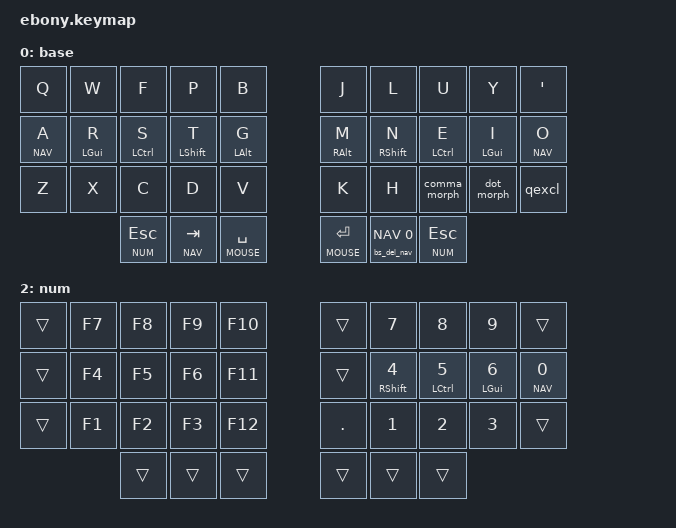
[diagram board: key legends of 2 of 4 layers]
#include <behaviors.dtsi>
#include <dt-bindings/zmk/keys.h>
#include <dt-bindings/zmk/bt.h>
#include <dt-bindings/zmk/outputs.h>
#include <dt-bindings/zmk/mouse.h>

#define DEF 0
#define NAV 1
#define NUM 2
#define MOUSE 3

#include "./key_positions.h"
#include "./helper.h"
#include "./combos.dtsi"


&mmv {
  acceleration-exponent = <1>;      // 1
  time-to-max-speed-ms = <1500>;    // 40
  delay-ms = <0>;                   // 0
};

&mwh {
  acceleration-exponent = <1>;      // 0
  time-to-max-speed-ms = <5000>;    // 40
  delay-ms = <0>;                   // 10
};

#define U_MOUSE_MOVE_MAX 1250       // 600
#define U_MOUSE_SCROLL_MAX 100      // 10

#undef MOVE_UP
#undef MOVE_DOWN
#undef MOVE_LEFT
#undef MOVE_RIGHT
#define MOVE_UP MOVE_VERT(-U_MOUSE_MOVE_MAX)
#define MOVE_DOWN MOVE_VERT(U_MOUSE_MOVE_MAX)
#define MOVE_LEFT MOVE_HOR(-U_MOUSE_MOVE_MAX)
#define MOVE_RIGHT MOVE_HOR(U_MOUSE_MOVE_MAX)

#undef SCROLL_UP
#undef SCROLL_DOWN
#undef SCROLL_LEFT
#undef SCROLL_RIGHT
#define SCROLL_UP SCROLL_VERT(U_MOUSE_SCROLL_MAX)
#define SCROLL_DOWN SCROLL_VERT(-U_MOUSE_SCROLL_MAX)
#define SCROLL_LEFT SCROLL_HOR(-U_MOUSE_SCROLL_MAX)
#define SCROLL_RIGHT SCROLL_HOR(U_MOUSE_SCROLL_MAX)

#define U_BTN1 &mkp MB1
#define U_BTN2 &mkp MB2
#define U_BTN3 &mkp MB3
#define U_MS_U &mmv MOVE_UP
#define U_MS_D &mmv MOVE_DOWN
#define U_MS_L &mmv MOVE_LEFT
#define U_MS_R &mmv MOVE_RIGHT
#define U_WH_U &mwh SCROLL_UP
#define U_WH_D &mwh SCROLL_DOWN
#define U_WH_L &mwh SCROLL_LEFT
#define U_WH_R &mwh SCROLL_RIGHT


#define XXX &none
#define ___ &trans

#define QUICK_TAP_MS 175

&sk {  // sticky-key config
    release-after-ms = <900>;  // release after 0.6s
    quick-release;             // no double capitalization when rolling keys
};

&sl {  // sticky-layer config
    ignore-modifiers;          // allow chording sticky mods & layers
};

&lt {  // layer-tap config
    flavor = "balanced";
    tapping-term-ms = <200>;
    quick-tap-ms = <QUICK_TAP_MS>;
};

/* Homerow mods */

#define KEYS_L LT0 LT1 LT2 LT3 LT4 LM0 LM1 LM2 LM3 LM4 LB0 LB1 LB2 LB3 LB4  // left hand
#define KEYS_R RT0 RT1 RT2 RT3 RT4 RM0 RM1 RM2 RM3 RM4 RB0 RB1 RB2 RB3 RB4  // right hand
#define THUMBS LH3 LH2 LH1 LH0 RH0 RH1 RH2 RH3

#define MAKE_HRM(NAME, HOLD, TAP, TRIGGER_POS) \
    ZMK_BEHAVIOR(NAME, hold_tap, \
        flavor = "balanced"; \
        tapping-term-ms = <280>; \
        quick-tap-ms = <QUICK_TAP_MS>; \
        #global-quick-tap-ms = <150>; \
        bindings = <HOLD>, <TAP>; \
        hold-trigger-key-positions = <TRIGGER_POS>; \
        hold-trigger-on-release; \
    )

MAKE_HRM(hml, &kp, &kp, KEYS_R THUMBS)  // left-hand HRMs
MAKE_HRM(hmr, &kp, &kp, KEYS_L THUMBS)  // right-hand HRMs

MAKE_HRM(hmll, &mo, &kp, KEYS_R THUMBS)  // left-hand HRMs
MAKE_HRM(hmlr, &mo, &kp, KEYS_L THUMBS)  // right-hand HRMs

MAKE_HRM(hml_repeat, &kp, &key_repeat, KEYS_R THUMBS)  // used for HRM-combo
MAKE_HRM(hmr_lpar_lt, &kp, &lpar_lt, KEYS_L THUMBS)    // "    "   "   "
MAKE_HRM(hmr_rpar_gt, &kp, &rpar_gt, KEYS_L THUMBS)    // "    "   "   "

/* Nav cluster */

// long-tap action on hold, short-tap action on all interrupts
#define MT_CORE \
    flavor = "tap-preferred"; \
    tapping-term-ms = <220>; \
    quick-tap-ms = <220>; \
    hold-trigger-key-positions = <0>;

&mt { MT_CORE };

#define NAV_BSPC  &mt LC(BSPC) BSPC    // tap: bspc  | long-tap: delete word backward
#define NAV_DEL   &mt LC(DEL)  DEL     // tap: del   | long-tap: delete word forward

/* Caps-word, num-word and smart-mouse */

// tap: sticky-shift | shift + tap/ double-tap: caps-word | hold: shift
ZMK_BEHAVIOR(smart_shft, mod_morph,
    bindings = <&kp RETURN>, <&caps_word>;
    mods = <(MOD_LSFT)>;
)
&caps_word {  // mods deactivate caps-word, requires PR #1451
    /delete-property/ ignore-modifiers;
};

// tap: num-word | double-tap: sticky num-layer | hold: num-layer
#define SMART_NUM &smart_num NUM 0
ZMK_BEHAVIOR(smart_num, hold_tap,
    flavor = "balanced";
    tapping-term-ms = <200>;
    quick-tap-ms = <QUICK_TAP_MS>;
    bindings = <&mo>, <&num_dance>;
)
ZMK_BEHAVIOR(num_dance, tap_dance,
    tapping-term-ms = <200>;
    bindings = <&num_word>, <&sl NUM>;  // reverse this for sticky-num on single tap
)
&num_word {  // num-word, requires PR #1451
    layers = <NUM>;
    continue-list = <BSPC DEL DOT COMMA PLUS MINUS STAR FSLH EQUAL>;
};

/* Custom behaviors */
// Sticky layer + sticky shift (workaround for issue #1421)
//ZMK_BEHAVIOR(sls, sticky_key,
//    release-after-ms = <1000>;
//    bindings = <&uc_shift>;
//    ignore-modifiers;
//)
//ZMK_BEHAVIOR(uc_shift, macro,
//    wait-ms = <0>;
//    tap-ms = <1>;
//    bindings = <&macro_press &mo UC &kp LSHFT>
//             , <&macro_pause_for_release>
//             , <&macro_release &mo UC &kp LSHFT>;
//)

// tap: comma | shift + tap: semicolon | ctrl + shift + tap: <
ZMK_BEHAVIOR(comma_morph, mod_morph,
    mods = <(MOD_LSFT|MOD_RSFT)>;
    bindings = <&kp COMMA>, <&comma_inner_morph>;
)
ZMK_BEHAVIOR(comma_inner_morph, mod_morph,
    bindings = <&kp SEMICOLON>, <&kp LESS_THAN>;
    mods = <(MOD_LCTL|MOD_RCTL)>;
)

// tap: dot | shift + tap: colon | ctrl + shift + tap: >
ZMK_BEHAVIOR(dot_morph, mod_morph,
    bindings = <&kp DOT>, <&dot_inner_morph>;
    mods = <(MOD_LSFT|MOD_RSFT)>;
)
ZMK_BEHAVIOR(dot_inner_morph, mod_morph,
    bindings = <&kp COLON>, <&kp GREATER_THAN>;
    mods = <(MOD_LCTL|MOD_RCTL)>;
)

// tap: qmark | shift + tap: excl
ZMK_BEHAVIOR(qexcl, mod_morph,
    bindings = <&kp QMARK>, <&kp EXCL>;
    mods = <(MOD_LSFT|MOD_RSFT)>;
)

// tap: space | shift + tap: dot -> space -> sticky shift | hold: activate layer
ZMK_BEHAVIOR(lt_spc, hold_tap,
    flavor = "balanced";
    tapping-term-ms = <200>;
    quick-tap-ms = <QUICK_TAP_MS>;
    bindings = <&mo>, <&spc_morph>;
)
ZMK_BEHAVIOR(spc_morph, mod_morph,
    bindings = <&kp SPACE>, <&dot_spc>;
    mods = <(MOD_LSFT|MOD_RSFT)>;
)
ZMK_BEHAVIOR(dot_spc, macro,
    wait-ms = <0>;
    tap-ms = <5>;
    bindings = <&kp DOT &kp SPACE &sk LSHFT>;
)
ZMK_BEHAVIOR(bs_del_nav, hold_tap,
	flavor = "balanced";
    tapping-term-ms = <200>;
    quick-tap-ms = <QUICK_TAP_MS>;
    bindings = <&mo>, <&bs_del>;
)

// tap: backspace | lshft + tap: delete | rshft + tap: shift-delete
ZMK_BEHAVIOR(bs_del, mod_morph,
    bindings = <&kp BSPC>, <&kp DEL>;
    mods = <(MOD_LSFT|MOD_RSFT)>;
    keep-mods = <MOD_RSFT>;
)

// tap: left-parenthesis | shft + tap: less-than
ZMK_BEHAVIOR(lpar_lt, mod_morph,
    bindings = <&kp LPAR>, <&kp LT>;
    mods = <(MOD_LSFT|MOD_RSFT)>;
)

// tap: right-parenthesis | shft + tap: greater-than
ZMK_BEHAVIOR(rpar_gt, mod_morph,
    bindings = <&kp RPAR>, <&kp GT>;
    mods = <(MOD_LSFT|MOD_RSFT)>;
)

// tap: copy | double-tap: cut
ZMK_BEHAVIOR(copy_cut, tap_dance,
    tapping-term-ms = <200>;
    bindings = <&kp LC(INS)>, <&kp LC(X)>;
)

// misc aliases
#define CANCEL      &kp K_CANCEL             // cancel caps-word, num-word and smart-mouse
#define DSK_PREV    &hmr LGUI LG(LC(LEFT))  // previous desktop
#define DSK_NEXT    &hmr LSHFT LG(LC(RIGHT))  // next     desktop
#define VOL_DOWN    &hml LGUI C_VOL_DN
#define VOL_UP      &hml LCTRL C_VOL_UP
#define MUTE        &hml LALT C_MUTE

ZMK_LAYER(base,
//╭───────────────┬──────────────┬──────────────┬──────────────┬──────────────╮   ╭──────────────┬──────────────┬──────────────┬───────────────┬──────────────╮
    &kp Q           &kp W          &kp F          &kp P          &kp B              &kp J          &kp L          &kp U          &kp Y           &kp SQT
//├───────────────┼──────────────┼──────────────┼──────────────┼──────────────┤   ├──────────────┼──────────────┼──────────────┼───────────────┼──────────────┤
    &hmll NAV A     &hml LGUI R    &hml LCTRL S   &hml LSHFT T   &hml LALT G        &hmr RALT M    &hmr RSHFT N   &hmr LCTRL E   &hmr LGUI I    &hmlr NAV O
//├───────────────┼──────────────┼──────────────┼──────────────┼──────────────┤   ├──────────────┼──────────────┼──────────────┼───────────────┼──────────────┤
    &kp Z           &kp X          &kp C          &kp D          &kp V              &kp K          &kp H          &comma_morph   &dot_morph     &qexcl
//├───────────────┴──────┬───────┴──────────────┼──────────────┴──────────────┤   ├──────────────┴──────────────┼──────────────┴───────┬───────┴──────────────┤
        &lt NUM ESC             &lt NAV TAB             &lt MOUSE SPACE                  &lt MOUSE RETURN          &bs_del_nav NAV 0         &lt NUM ESC
//╰──────────────────────┴──────────────────────┴─────────────────────────────╯   ╰─────────────────────────────┴──────────────────────┴──────────────────────╯
)
ZMK_LAYER(nav,
//╭───────────────┬──────────────┬──────────────┬──────────────┬──────────────╮   ╭──────────────┬──────────────┬──────────────┬───────────────┬──────────────╮
    &kp C_PREV      &kp C_RW       &kp C_PP       &kp C_FF       &kp C_NEXT         &kp PG_UP      &kp HOME       NAV_BSPC       NAV_DEL         &kp END
//├───────────────┼──────────────┼──────────────┼──────────────┼──────────────┤   ├──────────────┼──────────────┼──────────────┼───────────────┼──────────────┤
    &hmll NAV XXX   VOL_DOWN       VOL_UP        &hml LSHFT XXX  MUTE               &kp PG_DN      &kp LEFT       &kp DOWN       &kp UP          &kp RIGHT
//├───────────────┼──────────────┼──────────────┼──────────────┼──────────────┤   ├──────────────┼──────────────┼──────────────┼───────────────┼──────────────┤
    ___             ___            ___            ___            ___                &kp LALT       &kp TAB        &caps_word         ___         CANCEL
//├───────────────┴──────┬───────┴──────────────┼──────────────┴──────────────┤   ├──────────────┴──────────────┼──────────────┴───────┬───────┴──────────────┤
            ___                    ___                        ___                               ___                        ___                    ___
//╰──────────────────────┴──────────────────────┴─────────────────────────────╯   ╰─────────────────────────────┴──────────────────────┴──────────────────────╯
)
ZMK_LAYER(num,
//╭───────────────┬──────────────┬──────────────┬──────────────┬──────────────╮   ╭──────────────┬──────────────┬──────────────┬───────────────┬──────────────╮
        ___         &kp F7         &kp F8         &kp F9	     &kp F10            ___            &kp N7         &kp N8         &kp N9          ___
//├───────────────┼──────────────┼──────────────┼──────────────┼──────────────┤   ├──────────────┼──────────────┼──────────────┼───────────────┼──────────────┤
        ___         &kp F4         &kp F5         &kp F6         &kp F11            ___            &hmr RSHFT N4  &hmr LCTRL N5  &hmr LGUI N6    &hmlr NAV N0
//├───────────────┼──────────────┼──────────────┼──────────────┼──────────────┤   ├──────────────┼──────────────┼──────────────┼───────────────┼──────────────┤
        ___         &kp F1         &kp F2         &kp F3         &kp F12            &kp DOT        &kp N1         &kp N2         &kp N3          ___
//├───────────────┴──────┬───────┴──────────────┼──────────────┴──────────────┤   ├──────────────┴──────────────┼──────────────┴───────┬───────┴──────────────┤
            ___                    ___                        ___                               ___                        ___                    ___
//╰──────────────────────┴──────────────────────┴─────────────────────────────╯   ╰─────────────────────────────┴──────────────────────┴──────────────────────╯
)
ZMK_LAYER(mouse,
//╭───────────────┬──────────────┬──────────────┬──────────────┬──────────────╮   ╭──────────────┬──────────────┬──────────────┬───────────────┬──────────────╮
    &bt BT_SEL 0    &bt BT_SEL 1   &bt BT_SEL 2   &bt BT_SEL 3   &bt BT_SEL 4       ___            ___            U_WH_D         U_WH_U
//├───────────────┼──────────────┼──────────────┼──────────────┼──────────────┤   ├──────────────┼──────────────┼──────────────┼───────────────┼──────────────┤
    ___             &kp LGUI       U_MS_R            U_MS_L            &kp LALT           ___            U_MS_L         U_MS_D         U_MS_U          U_MS_R
//├───────────────┼──────────────┼──────────────┼──────────────┼──────────────┤   ├──────────────┼──────────────┼──────────────┼───────────────┼──────────────┤
    ___             &bt BT_CLR     &out OUT_TOG   &sys_reset     &bootloader        &bootloader    &sys_reset     &out OUT_TOG   &bt BT_CLR      ___
//├───────────────┴──────┬───────┴──────────────┼──────────────┴──────────────┤   ├──────────────┴──────────────┼──────────────┴───────┬───────┴──────────────┤
             ___                   ___                        ___                              ___                    ___                 ___
//             ___                   ___                        ___                              U_BTN1                    U_BTN2                 U_BTN3
//╰──────────────────────┴──────────────────────┴─────────────────────────────╯   ╰─────────────────────────────┴──────────────────────┴──────────────────────╯
)
